# w600 register map
File version: v0.1
Registers are 32-bit, read-write, reset 0x0 unless marked. A register's access mark holds for its fields unless they carry their own. Offsets are from the block's base; [hi:lo] are bit positions.

## i2c
Base 0x40010000
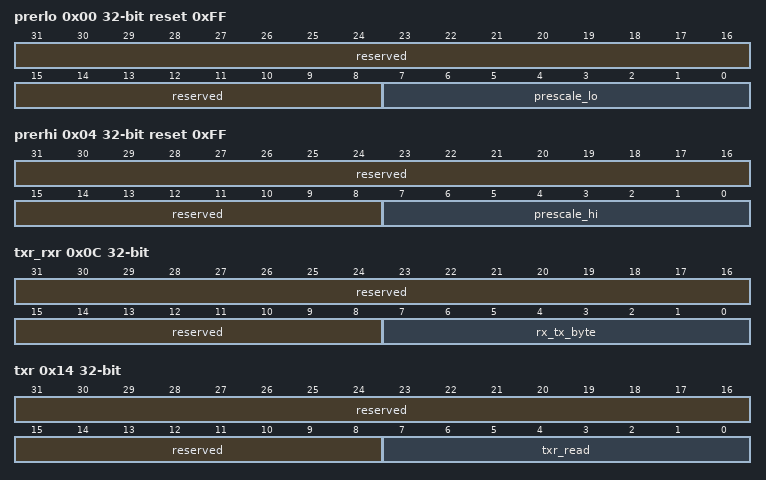
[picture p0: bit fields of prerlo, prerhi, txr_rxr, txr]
0x00 prerlo reset 0xFF — 存放低 8 位的分频值，用以对 APB总线时钟进行分频
  [31:8] reserved — 保留
  [7:0] prescale_lo — 时钟分频配置prescale 的低 8bit。例如：apb_clk=40MHz, SCL=100KHzprescale = (40*1000)/(5*100) – 1 = 16’d79 apb_clk = 40M, SCL=400Kprescale=(40*1000)/(5*400) – 1 = 16’d19
0x04 prerhi reset 0xFF — 存放高 8 位的分频值，用以对 APB总线时钟进行分频
  [31:8] reserved — 保留
  [7:0] prescale_hi — 时钟分频配置prescale 的高 8bit。例如：apb_clk=40MHz, SCL=100KHzprescale = (40*1000)/(5*100) – 1 = 16’d79 apb_clk = 40M, SCL=400Kprescale=(40*1000)/(5*400) – 1 = 16’d19
0x08 ctr reset 0x40 — 用以控制中断的使能以及I2S 控制器的使能
  [31:8] reserved — 保留
  [0] i2c_en — 使能控制，
    0=不使能; 1=使能
  [0] int_mask
    0=允许中断产生; 1=不允许中断产生
  [5:0] reserved — 保留
0x0C txr_rxr — 用以存放待发送的数据或者接收到的数据
  [31:8] reserved — 保留
  [7:0] rx_tx_byte — 写该寄存器时，为发送寄存器TXR，表示下一个要发送的字节，当为设备地址时，[0]：1 时表示读，0 时表示写。读该寄存器时，为接收寄存器RXR，为最新从I2C 上接收到的字节。
0x10 cr_sr — 用以控制一些数据读写相关的操作
  [5:2] reserved ro — 保留
  [2:1] reserved — 保留
  [0] sta — ，控制产生START 时序
    0=无效; 1=产生START 时序
  [0] sto — ，控制产生STOP 时序；
    0=无效
  [0] rd — ，从 SLAVE 读；
    0=无效; 1=从SLAVE 读
  [0] wr — ，向 SLAVE 写；
    0=无效; 1=向SLAVE 写
  [0] ack_nack — 控制向SLAVE 送回 ACK/NACK；
    0=回ACK; 1=回NAK
  [0] iack — ，清除中断状态，1 有效；
    0=无效; 1=清除中断标志
  [0] rxack ro — ，从SLAVE 收到的ACK/NACK 状态；
    on read: 0=从SLAVE 收到 ACK; 1=从SLAVE 收到NAK
  [0] busy ro — ；
    on read: 0=STO 后置 0; 1=STA 后置 1
  [0] tip ro — ；
    on read: 0=无传输正在进行; 1=有传输正在进行
  [0] if ro — ，中断状态位；
    on read: 0=无中断产生; 1=传输完成
0x14 txr ro — 读取I2C 发送时的TXR 寄存器值
  [31:8] reserved — 保留
  [7:0] txr_read — 只读，TXR 寄存器的读出值，功能描述见TXR_RXR 寄存器；
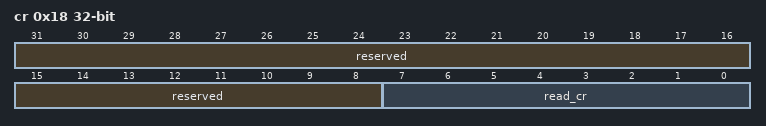
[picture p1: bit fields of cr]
0x18 cr ro — 读取I2C 控制寄存器的设定值 CR
  [31:8] reserved — 保留
  [7:0] read_cr — 只读，CR 寄存器的读出值，功能描述见CR_SR 寄存器；

## pmu — Power Managent Unit
Base 0x40000600
0x00 ps_cr reset 0x2 — 用于配置32K 校准，配置32K 时钟源，设置芯片的STANDBY 功能
  [31:8] reserved ro — 保留
  [7:4] reserved — 保留
  [0] bypass — 32K 振荡电路BYPASS 信号，高有效。 当芯片进入STANBY 状态， 32K 时钟自动切换为振荡电路产生的 32K 时钟。芯片唤醒后，如需继续使用 40M 分频的 32K 时钟，需重新置位为 1。
    0=32K 由振荡电路产生; 1=32K 由 40M 时钟分频得到
  [0] rc_switch — RC 32K 振荡器校准电路启动开关； 要启动校准功能，需要此位先置 0，后置 1。
    0=校准电路复位；; 1=启动校准电路；
  [0] reserved — 保留
  [0] standby_en — 使能信号，高有效。 如果 WAKEUP 脚为无效电平，且没有配置TIMER0/1 中断唤醒，则该寄存器有效时，芯片进入STANDBY 状态； 如果唤醒中断产生，则芯片会从 STANDBY 状态切换到唤醒状态，唤醒条件满足，该位自动清 0。 唤醒源：WAKEUP 脚，TIMER0/TIMER1，RTC 1） WAKEUP 脚，高有效；要想芯片进入 STANDBY 状态，WAKEUP 脚必须处于低电平。要唤醒时，拉高 WAKEUP 脚，产生唤醒中断，使芯片离开STANDBY 状态。 2） TIMER0，定时器唤醒中断。 当 WAKEUP 脚为低，TIMER0 设置定时时间并使能，定时时间到会产生唤醒中断，使芯片离开STANDBY 状态。 3） RTC，定时时间到唤醒 当 WAKEUP 脚为低，RTC 定时时间到，会产生唤醒中断，使芯片离开 STANDBY 状态
    0=芯片唤醒状态; 1=芯片进入STANDBY 状态
0x04 timer0 — 配置定时值（单位为秒），使能定时器
  [31:17] reserved ro — 保留
  [0] timer0_en — 使能位
    0=位使能。; 1=使能；
  [15:0] timer0_value — 的定时值，单位:秒
0x14 int_src — 提供PMU中断标志
  [31:9] reserved ro — 保留
  [0] lasted_status — 显示当次上电状态：
    0=上电或复位启动; 1=从休眠状态唤醒，写 1 清除
  [0] reserved ro — 保留
  [0] reserved ro — 保留
  [0] rtc_int — RTC 定时中断标志位：
    0=有定时中断产生; 1=无定时中断产生，写 1 清除
  [0] reserved — 保留
  [0] reserved — 保留
  [0] wakeup_int — 管脚唤醒中断标志位
    0=无 WAKEUP 唤醒中断产生; 1=有 WAEKUP 唤醒中断产生，写 1 清除
  [0] reserved — 保留
  [0] timer0_int — 定时中断标志位：
    0=无Timer0 中断产生; 1=有Timer0 中断产生，写 1 清除

## rsa
Base 0x40002200
0x00 xbuf reset not defined — 数据X 寄存器
0x100 ybuf reset not defined — 数据Y 寄存器
0x200 mbuf reset not defined — 数据M 寄存器
0x300 dbuf reset not defined — 数据D 寄存器
0x400 rsacon — RSA 控制寄存器
  [31:6] reserved — 保留
  [3:2] mul_mode — 模乘模式选择。
    0=X = D*D mod M; 1=D = X*Y mod M; 2=X = D*Y mod M; 3=D = X*X mod M
  [0] mul_start — 模乘启动控制位。软件写“1”启动模乘运算，运算结束后，硬件自动清“0”。
  [0] soft_reset — 提供软复位功能，高有效。软件写“1”进行软复位，复位完成后，硬件自动清“0”。 1.设置参数MC 和N 为 0。 2.启动模乘后（bit5 置 1），将此位置“1”，会终止当前的运算（当 bit0 变高，表示软复位命令执行完成，运算被终止），但内部数据缓冲区（X，Y，M，D）中已经完成的部分运算结果会保留。
  [0] reserved — 保留
  [0] mul_complete — 模乘运算完成标识，高有效。硬件置“1”，软件清“0”。软件写“1”无效。
0x404 rsamc — 参数MC 寄存器
  [31:0] rsamc — 对应参数MC（32bit）。复位值全 0。读出值为全 0。
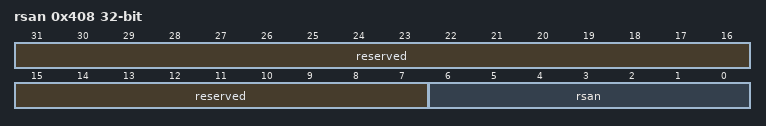
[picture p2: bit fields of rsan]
0x408 rsan — 参数N 寄存器
  [31:7] reserved — 保留
  [6:0] rsan — 对应参数 N（7bit）。N 值为模乘长度除以 32 的值。
